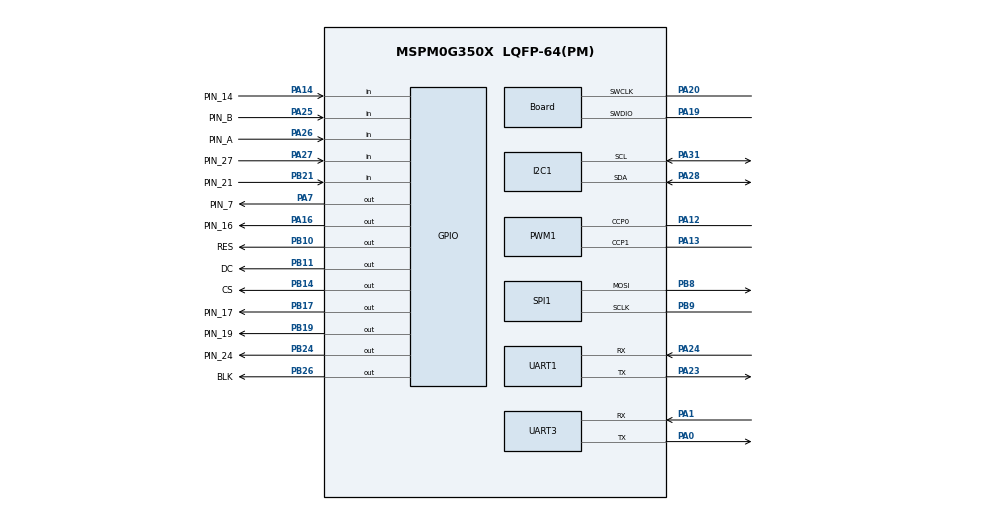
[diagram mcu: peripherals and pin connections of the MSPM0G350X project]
/**
 * @cliArgs --device "MSPM0G350X" --part "Default" --package "LQFP-64(PM)" --product "mspm0_sdk@2.09.00.00"
 * @versions {"tool":"1.26.0+4407"}
 */

/**
 * Import the modules used in this configuration.
 */
const GPIO   = scripting.addModule("/ti/driverlib/GPIO", {}, false);
const GPIO1  = GPIO.addInstance();
const GPIO2  = GPIO.addInstance();
const GPIO3  = GPIO.addInstance();
const GPIO4  = GPIO.addInstance();
const GPIO5  = GPIO.addInstance();
const GPIO6  = GPIO.addInstance();
const GPIO7  = GPIO.addInstance();
const GPIO8  = GPIO.addInstance();
const GPIO9  = GPIO.addInstance();
const GPIO10 = GPIO.addInstance();
const GPIO11 = GPIO.addInstance();
const GPIO12 = GPIO.addInstance();
const I2C    = scripting.addModule("/ti/driverlib/I2C", {}, false);
const I2C1   = I2C.addInstance();
const PWM    = scripting.addModule("/ti/driverlib/PWM", {}, false);
const PWM1   = PWM.addInstance();
const SPI    = scripting.addModule("/ti/driverlib/SPI", {}, false);
const SPI1   = SPI.addInstance();
const SYSCTL = scripting.addModule("/ti/driverlib/SYSCTL");
const TIMER  = scripting.addModule("/ti/driverlib/TIMER", {}, false);
const TIMER1 = TIMER.addInstance();
const TIMER2 = TIMER.addInstance();
const UART   = scripting.addModule("/ti/driverlib/UART", {}, false);
const UART1  = UART.addInstance();
const UART3  = UART.addInstance();

/**
 * Write custom configuration values to the imported modules.
 */
const divider7       = system.clockTree["PLL_PDIV"];
divider7.divideValue = 2;

const divider9       = system.clockTree["UDIV"];
divider9.divideValue = 2;

const multiplier2         = system.clockTree["PLL_QDIV"];
multiplier2.multiplyValue = 5;

const mux8       = system.clockTree["HSCLKMUX"];
mux8.inputSelect = "HSCLKMUX_SYSPLL2X";

GPIO1.$name                          = "AIN1";
GPIO1.associatedPins[0].$name        = "PIN_17";
GPIO1.associatedPins[0].assignedPort = "PORTB";
GPIO1.associatedPins[0].assignedPin  = "17";
GPIO1.associatedPins[0].pin.$assign  = "PB17";

const Board                       = scripting.addModule("/ti/driverlib/Board", {}, false);
Board.peripheral.$assign          = "DEBUGSS";
Board.peripheral.swclkPin.$assign = "PA20";
Board.peripheral.swdioPin.$assign = "PA19";

GPIO2.$name                          = "AIN2";
GPIO2.associatedPins[0].$name        = "PIN_19";
GPIO2.associatedPins[0].assignedPort = "PORTB";
GPIO2.associatedPins[0].assignedPin  = "19";
GPIO2.associatedPins[0].pin.$assign  = "PB19";

GPIO3.$name                          = "BIN1";
GPIO3.associatedPins[0].$name        = "PIN_16";
GPIO3.associatedPins[0].assignedPort = "PORTA";
GPIO3.associatedPins[0].assignedPin  = "16";
GPIO3.associatedPins[0].pin.$assign  = "PA16";

GPIO4.$name                          = "BIN2";
GPIO4.associatedPins[0].$name        = "PIN_24";
GPIO4.associatedPins[0].assignedPort = "PORTB";
GPIO4.associatedPins[0].assignedPin  = "24";
GPIO4.associatedPins[0].pin.$assign  = "PB24";

GPIO5.$name                          = "GPIO_ENCODER";
GPIO5.associatedPins.create(2);
GPIO5.associatedPins[0].$name        = "PIN_A";
GPIO5.associatedPins[0].direction    = "INPUT";
GPIO5.associatedPins[0].assignedPort = "PORTA";
GPIO5.associatedPins[0].assignedPin  = "26";
GPIO5.associatedPins[0].interruptEn  = true;
GPIO5.associatedPins[0].polarity     = "RISE";
GPIO5.associatedPins[0].pin.$assign  = "PA26";
GPIO5.associatedPins[1].$name        = "PIN_B";
GPIO5.associatedPins[1].direction    = "INPUT";
GPIO5.associatedPins[1].assignedPort = "PORTA";
GPIO5.associatedPins[1].assignedPin  = "25";
GPIO5.associatedPins[1].interruptEn  = true;
GPIO5.associatedPins[1].polarity     = "RISE";
GPIO5.associatedPins[1].pin.$assign  = "PA25";

GPIO6.$name                          = "BUZZER";
GPIO6.associatedPins[0].$name        = "PIN_7";
GPIO6.associatedPins[0].assignedPort = "PORTA";
GPIO6.associatedPins[0].assignedPin  = "7";
GPIO6.associatedPins[0].pin.$assign  = "PA7";

GPIO7.$name                          = "ENC_A_DIR";
GPIO7.associatedPins[0].$name        = "PIN_27";
GPIO7.associatedPins[0].direction    = "INPUT";
GPIO7.associatedPins[0].assignedPort = "PORTA";
GPIO7.associatedPins[0].assignedPin  = "27";
GPIO7.associatedPins[0].pin.$assign  = "PA27";

GPIO8.$name                          = "ENC_B_DIR";
GPIO8.associatedPins[0].$name        = "PIN_14";
GPIO8.associatedPins[0].direction    = "INPUT";
GPIO8.associatedPins[0].assignedPort = "PORTA";
GPIO8.associatedPins[0].assignedPin  = "14";
GPIO8.associatedPins[0].pin.$assign  = "PA14";

GPIO9.$name                              = "RUN_BUTTON";
GPIO9.associatedPins[0].$name            = "PIN_21";
GPIO9.associatedPins[0].direction        = "INPUT";
GPIO9.associatedPins[0].internalResistor = "PULL_UP";
GPIO9.associatedPins[0].assignedPort     = "PORTB";
GPIO9.associatedPins[0].assignedPin      = "21";
GPIO9.associatedPins[0].pin.$assign      = "PB21";

GPIO10.$name                          = "SCL";
GPIO10.associatedPins[0].assignedPort = "PORTB";
GPIO10.associatedPins[0].assignedPin  = "15";
GPIO10.associatedPins[0].$name        = "SCK_PIN";
GPIO10.associatedPins[0].initialValue = "SET";

GPIO11.$name                          = "SDA";
GPIO11.associatedPins[0].$name        = "SDA_PIN";
GPIO11.associatedPins[0].assignedPort = "PORTB";
GPIO11.associatedPins[0].assignedPin  = "5";
GPIO11.associatedPins[0].initialValue = "SET";
GPIO11.associatedPins[0].direction    = "INPUT";

GPIO12.$name                              = "LCD";
GPIO12.port                               = "PORTB";
GPIO12.associatedPins.create(4);
GPIO12.associatedPins[0].$name            = "RES";
GPIO12.associatedPins[0].initialValue     = "SET";
GPIO12.associatedPins[0].assignedPin      = "10";
GPIO12.associatedPins[0].pin.$assign      = "PB10";
GPIO12.associatedPins[1].$name            = "DC";
GPIO12.associatedPins[1].initialValue     = "SET";
GPIO12.associatedPins[1].assignedPin      = "11";
GPIO12.associatedPins[1].pin.$assign      = "PB11";
GPIO12.associatedPins[2].$name            = "CS";
GPIO12.associatedPins[2].initialValue     = "SET";
GPIO12.associatedPins[2].assignedPin      = "14";
GPIO12.associatedPins[2].pin.$assign      = "PB14";
GPIO12.associatedPins[3].$name            = "BLK";
GPIO12.associatedPins[3].assignedPin      = "26";
GPIO12.associatedPins[3].pin.$assign      = "PB26";

I2C1.$name                             = "I2C_VL53L0X";
I2C1.basicEnableController             = true;
I2C1.basicControllerBusSpeed           = 400000;
I2C1.basicControllerStandardBusSpeed   = "Fast";
I2C1.peripheral.$assign                = "I2C0";
I2C1.peripheral.sdaPin.$assign         = "PA28";
I2C1.peripheral.sclPin.$assign         = "PA31";
I2C1.sdaPinConfig.hideOutputInversion  = scripting.forceWrite(false);
I2C1.sdaPinConfig.onlyInternalResistor = scripting.forceWrite(false);
I2C1.sdaPinConfig.passedPeripheralType = scripting.forceWrite("Digital");
I2C1.sdaPinConfig.$name                = "ti_driverlib_gpio_GPIOPinGeneric1";
I2C1.sclPinConfig.hideOutputInversion  = scripting.forceWrite(false);
I2C1.sclPinConfig.onlyInternalResistor = scripting.forceWrite(false);
I2C1.sclPinConfig.passedPeripheralType = scripting.forceWrite("Digital");
I2C1.sclPinConfig.$name                = "ti_driverlib_gpio_GPIOPinGeneric2";

PWM1.$name                              = "PWM_MOTOR";
PWM1.clockDivider                       = 8;
PWM1.timerStartTimer                    = true;
PWM1.peripheral.$assign                 = "TIMG0";
PWM1.peripheral.ccp0Pin.$assign         = "PA12";
PWM1.peripheral.ccp1Pin.$assign         = "PA13";
PWM1.PWM_CHANNEL_0.$name                = "ti_driverlib_pwm_PWMTimerCC0";
PWM1.PWM_CHANNEL_1.$name                = "ti_driverlib_pwm_PWMTimerCC1";
PWM1.ccp0PinConfig.direction            = scripting.forceWrite("OUTPUT");
PWM1.ccp0PinConfig.hideOutputInversion  = scripting.forceWrite(false);
PWM1.ccp0PinConfig.onlyInternalResistor = scripting.forceWrite(false);
PWM1.ccp0PinConfig.passedPeripheralType = scripting.forceWrite("Digital");
PWM1.ccp0PinConfig.$name                = "ti_driverlib_gpio_GPIOPinGeneric3";
PWM1.ccp1PinConfig.direction            = scripting.forceWrite("OUTPUT");
PWM1.ccp1PinConfig.hideOutputInversion  = scripting.forceWrite(false);
PWM1.ccp1PinConfig.onlyInternalResistor = scripting.forceWrite(false);
PWM1.ccp1PinConfig.passedPeripheralType = scripting.forceWrite("Digital");
PWM1.ccp1PinConfig.$name                = "ti_driverlib_gpio_GPIOPinGeneric4";

SPI1.$name                      = "SPI_LCD";
SPI1.direction                  = "PICO";
SPI1.frameFormat                = "MOTO3";
SPI1.targetBitRate              = 8000000;
SPI1.peripheral.$assign         = "SPI1";
SPI1.peripheral.sclkPin.$assign = "PB9";
SPI1.peripheral.mosiPin.$assign = "PB8";
SPI1.sclkPinConfig.$name        = "LCD_SPI_SCLK";
SPI1.mosiPinConfig.$name        = "LCD_SPI_MOSI";

SYSCTL.forceDefaultClkConfig = true;
SYSCTL.clockTreeEn           = true;

TIMER1.$name              = "TIMER_100MS";
TIMER1.timerStartTimer    = true;
TIMER1.timerMode          = "PERIODIC_UP";
TIMER1.timerPeriod        = "100ms";
TIMER1.timerClkDiv        = 8;
TIMER1.timerClkPrescale   = 100;
TIMER1.interrupts         = ["ZERO"];
TIMER1.peripheral.$assign = "TIMA0";

TIMER2.$name              = "TIMER_10MS";
TIMER2.timerClkDiv        = 8;
TIMER2.timerClkPrescale   = 100;
TIMER2.timerMode          = "PERIODIC";
TIMER2.timerStartTimer    = true;
TIMER2.timerPeriod        = "10 ms";
TIMER2.interrupts         = ["ZERO"];
TIMER2.peripheral.$assign = "TIMG6";

UART1.$name                    = "UART_0";
UART1.targetBaudRate           = 115200;
UART1.enableFIFO               = true;
UART1.rxFifoThreshold          = "DL_UART_RX_FIFO_LEVEL_ONE_ENTRY";
UART1.enableDMARX              = false;
UART1.enableDMATX              = false;
UART1.enabledInterrupts        = ["RX"];
UART1.peripheral.$assign       = "UART2";
UART1.peripheral.rxPin.$assign = "PA24";
UART1.peripheral.txPin.$assign = "PA23";
UART1.txPinConfig.$name        = "ti_driverlib_gpio_GPIOPinGeneric6";
UART1.rxPinConfig.$name        = "ti_driverlib_gpio_GPIOPinGeneric7";

UART3.$name                            = "UART_GYRO";
UART3.targetBaudRate                   = 115200;
UART3.enabledInterrupts                = ["RX"];
UART3.peripheral.$assign               = "UART0";
UART3.peripheral.rxPin.$assign         = "PA1";
UART3.peripheral.txPin.$assign         = "PA0";
UART3.txPinConfig.direction            = scripting.forceWrite("OUTPUT");
UART3.txPinConfig.hideOutputInversion  = scripting.forceWrite(false);
UART3.txPinConfig.onlyInternalResistor = scripting.forceWrite(false);
UART3.txPinConfig.passedPeripheralType = scripting.forceWrite("Digital");
UART3.txPinConfig.$name                = "ti_driverlib_gpio_GPIOPinGeneric0";
UART3.rxPinConfig.hideOutputInversion  = scripting.forceWrite(false);
UART3.rxPinConfig.onlyInternalResistor = scripting.forceWrite(false);
UART3.rxPinConfig.passedPeripheralType = scripting.forceWrite("Digital");
UART3.rxPinConfig.$name                = "ti_driverlib_gpio_GPIOPinGeneric10";

const ProjectConfig              = scripting.addModule("/ti/project_config/ProjectConfig", {}, false);
ProjectConfig.migrationCondition = true;

/**
 * Pinmux solution for unlocked pins/peripherals. This ensures that minor changes to the automatic solver in a future
 * version of the tool will not impact the pinmux you originally saw.  These lines can be completely deleted in order to
 * re-solve from scratch.
 */
GPIO10.associatedPins[0].pin.$suggestSolution = "PB15";
GPIO11.associatedPins[0].pin.$suggestSolution = "PB5";
